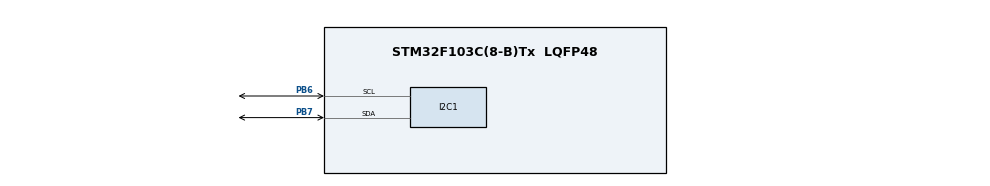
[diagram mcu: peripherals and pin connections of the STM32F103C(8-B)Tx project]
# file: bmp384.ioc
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Mcu.Family=STM32F1
Mcu.Name=STM32F103C(8-B)Tx
Mcu.Package=LQFP48
NVIC.PriorityGroup=NVIC_PRIORITYGROUP_4
PB6.Mode=I2C
PB6.Signal=I2C1_SCL
PB7.Mode=I2C
PB7.Signal=I2C1_SDA
ProjectManager.HeapSize=0x200
ProjectManager.StackSize=0x400
ProjectManager.TargetToolchain=STM32CubeIDE
RCC.APB1Freq_Value=8000000
RCC.APB2Freq_Value=8000000
VP_SYS_VS_ND.Mode=No_Debug
board=custom

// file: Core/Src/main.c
/* USER CODE BEGIN Header */
/**
  ******************************************************************************
  * @file           : main.c
  * @brief          : Main program body
  ******************************************************************************
  * @attention
  *
  * Copyright (c) 2024 STMicroelectronics.
  * All rights reserved.
  *
  * This software is licensed under terms that can be found in the LICENSE file
  * in the root directory of this software component.
  * If no LICENSE file comes with this software, it is provided AS-IS.
  *
  ******************************************************************************
  */
/* USER CODE END Header */
#include "main.h"

/* USER CODE BEGIN Includes */

#include <math.h>

/* USER CODE END Includes */

I2C_HandleTypeDef hi2c1;

/* USER CODE BEGIN PV */

#define BMP384_ADDR 0x77 << 1  // Adres I²C czujnika BMP384
#define REG_PWR_CTRL 0x1B
#define REG_OSR 0x1C
#define REG_PRESS_MSB 0x06
#define REG_TEMP_MSB 0x09
#define CMD_FORCE_MODE 0x01

extern I2C_HandleTypeDef hi2c1;

/* USER CODE END PV */

void SystemClock_Config(void);
static void MX_GPIO_Init(void);
static void MX_I2C1_Init(void);

int main(void)
{

  /* MCU Configuration--------------------------------------------------------*/

  /* Reset of all peripherals, Initializes the Flash interface and the Systick. */
  HAL_Init();

  /* Configure the system clock */
  SystemClock_Config();

  /* Initialize all configured peripherals */
  MX_GPIO_Init();
  MX_I2C1_Init();
  /* USER CODE BEGIN 2 */

  BMP384_Init();
  HAL_Delay(100);

  /* USER CODE END 2 */

  /* Infinite loop */
  while (1)
  {

    /* USER CODE BEGIN 3 */
  uint32_t pressure_raw;
  float altitude;

  pressure_raw = BMP384_ReadPressureRaw();
  altitude = BMP384_CalculateAltitude(pressure_raw);

  //printf("Ciśnienie surowe: %lu, Wysokość: %.2f m\n", pressure_raw, altitude);
  HAL_Delay(1000);

  }
  /* USER CODE END 3 */
}

void SystemClock_Config(void)
{
  RCC_OscInitTypeDef RCC_OscInitStruct = {0};
  RCC_ClkInitTypeDef RCC_ClkInitStruct = {0};

  /** Initializes the RCC Oscillators according to the specified parameters
  * in the RCC_OscInitTypeDef structure.
  */
  RCC_OscInitStruct.OscillatorType = RCC_OSCILLATORTYPE_HSI;
  RCC_OscInitStruct.HSIState = RCC_HSI_ON;
  RCC_OscInitStruct.HSICalibrationValue = RCC_HSICALIBRATION_DEFAULT;
  RCC_OscInitStruct.PLL.PLLState = RCC_PLL_NONE;
  if (HAL_RCC_OscConfig(&RCC_OscInitStruct) != HAL_OK)
  {
    Error_Handler();
  }

  /** Initializes the CPU, AHB and APB buses clocks
  */
  RCC_ClkInitStruct.ClockType = RCC_CLOCKTYPE_HCLK|RCC_CLOCKTYPE_SYSCLK
                              |RCC_CLOCKTYPE_PCLK1|RCC_CLOCKTYPE_PCLK2;
  RCC_ClkInitStruct.SYSCLKSource = RCC_SYSCLKSOURCE_HSI;
  RCC_ClkInitStruct.AHBCLKDivider = RCC_SYSCLK_DIV1;
  RCC_ClkInitStruct.APB1CLKDivider = RCC_HCLK_DIV1;
  RCC_ClkInitStruct.APB2CLKDivider = RCC_HCLK_DIV1;

  if (HAL_RCC_ClockConfig(&RCC_ClkInitStruct, FLASH_LATENCY_0) != HAL_OK)
  {
    Error_Handler();
  }
}

static void MX_I2C1_Init(void)
{

  hi2c1.Instance = I2C1;
  hi2c1.Init.ClockSpeed = 100000;
  hi2c1.Init.DutyCycle = I2C_DUTYCYCLE_2;
  hi2c1.Init.OwnAddress1 = 0;
  hi2c1.Init.AddressingMode = I2C_ADDRESSINGMODE_7BIT;
  hi2c1.Init.DualAddressMode = I2C_DUALADDRESS_DISABLE;
  hi2c1.Init.OwnAddress2 = 0;
  hi2c1.Init.GeneralCallMode = I2C_GENERALCALL_DISABLE;
  hi2c1.Init.NoStretchMode = I2C_NOSTRETCH_DISABLE;
  if (HAL_I2C_Init(&hi2c1) != HAL_OK)
  {
    Error_Handler();
  }

}

static void MX_GPIO_Init(void)
{

  /* GPIO Ports Clock Enable */
  __HAL_RCC_GPIOB_CLK_ENABLE();

}

/* USER CODE BEGIN 4 */

void BMP384_Init() {
    uint8_t data[2];

    // Ustawienie trybu pracy na forced mode
    data[0] = REG_PWR_CTRL;
    data[1] = CMD_FORCE_MODE;
    HAL_I2C_Master_Transmit(&hi2c1, BMP384_ADDR, data, 2, HAL_MAX_DELAY);

    // Ustawienie oversamplingu (ciśnienie x4, temperatura x1)
    data[0] = REG_OSR;
    data[1] = 0x22;  // osr_t = x1, osr_p = x4
    HAL_I2C_Master_Transmit(&hi2c1, BMP384_ADDR, data, 2, HAL_MAX_DELAY);
}

uint32_t BMP384_ReadPressureRaw() {
    uint8_t press_data[3];
    HAL_I2C_Mem_Read(&hi2c1, BMP384_ADDR, REG_PRESS_MSB, 1, press_data, 3, HAL_MAX_DELAY);
    return (press_data[0] << 16) | (press_data[1] << 8) | press_data[2];
}

uint32_t BMP384_ReadTemperatureRaw() {
    uint8_t temp_data[3];
    HAL_I2C_Mem_Read(&hi2c1, BMP384_ADDR, REG_TEMP_MSB, 1, temp_data, 3, HAL_MAX_DELAY);
    return (temp_data[0] << 16) | (temp_data[1] << 8) | temp_data[2];
}

float BMP384_CalculateAltitude(uint32_t pressure_raw) {
    const float sea_level_pressure = 101325.0;
    float pressure = (float)pressure_raw / 256.0;
    return 44330.0 * (1.0 - pow(pressure / sea_level_pressure, 0.1903));
}

/* USER CODE END 4 */

void Error_Handler(void)
{
  __disable_irq();
  while (1)
  {
  }
}
